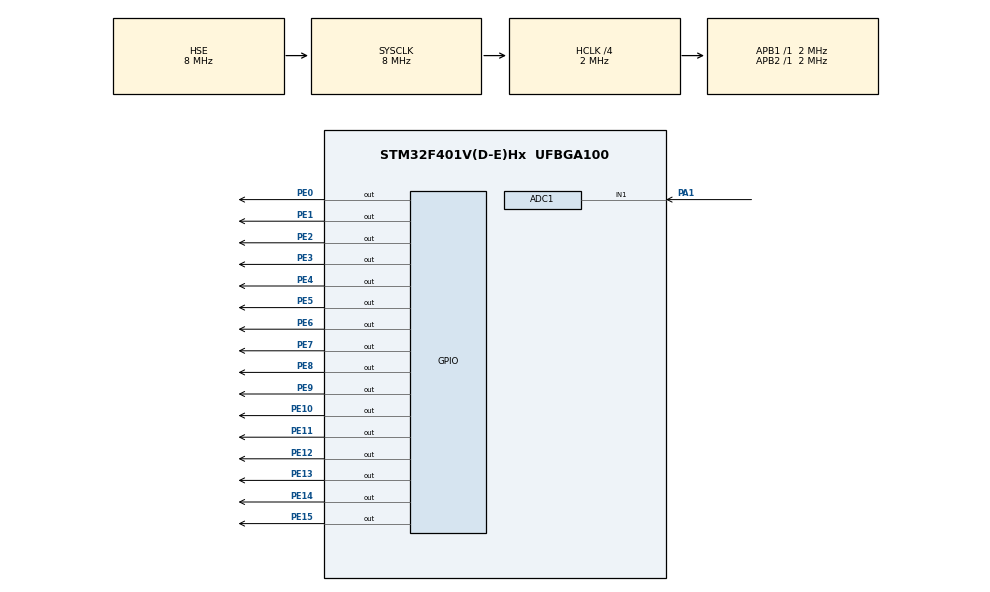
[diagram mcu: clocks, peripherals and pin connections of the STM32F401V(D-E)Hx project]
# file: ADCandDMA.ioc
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ADC1.Channel-1\#ChannelRegularConversion=ADC_CHANNEL_1
ADC1.ContinuousConvMode=ENABLE
ADC1.DMAContinuousRequests=DISABLE
ADC1.NbrOfConversion=1
ADC1.NbrOfConversionFlag=1
ADC1.Rank-1\#ChannelRegularConversion=1
ADC1.Resolution=ADC_RESOLUTION_10B
ADC1.SamplingTime-1\#ChannelRegularConversion=ADC_SAMPLETIME_84CYCLES
ADC1.ScanConvMode=DISABLE
ADC1.master=1
Mcu.Family=STM32F4
Mcu.Name=STM32F401V(D-E)Hx
Mcu.Package=UFBGA100
NVIC.ADC_IRQn=true\:0\:0\:false\:false\:true\:true\:true
NVIC.PriorityGroup=NVIC_PRIORITYGROUP_4
PA1.Signal=ADCx_IN1
PE0.GPIO_ModeDefaultOutputPP=GPIO_MODE_OUTPUT_PP
PE0.GPIO_PuPd=GPIO_NOPULL
PE0.GPIO_Speed=GPIO_SPEED_FREQ_HIGH
PE0.PinState=GPIO_PIN_RESET
PE0.Signal=GPIO_Output
PE1.GPIO_ModeDefaultOutputPP=GPIO_MODE_OUTPUT_PP
PE1.GPIO_PuPd=GPIO_NOPULL
PE1.GPIO_Speed=GPIO_SPEED_FREQ_HIGH
PE1.PinState=GPIO_PIN_RESET
PE1.Signal=GPIO_Output
PE10.GPIO_ModeDefaultOutputPP=GPIO_MODE_OUTPUT_PP
PE10.GPIO_PuPd=GPIO_NOPULL
PE10.GPIO_Speed=GPIO_SPEED_FREQ_HIGH
PE10.PinState=GPIO_PIN_RESET
PE10.Signal=GPIO_Output
PE11.GPIO_ModeDefaultOutputPP=GPIO_MODE_OUTPUT_PP
PE11.GPIO_PuPd=GPIO_NOPULL
PE11.GPIO_Speed=GPIO_SPEED_FREQ_HIGH
PE11.PinState=GPIO_PIN_RESET
PE11.Signal=GPIO_Output
PE12.GPIO_ModeDefaultOutputPP=GPIO_MODE_OUTPUT_PP
PE12.GPIO_PuPd=GPIO_NOPULL
PE12.GPIO_Speed=GPIO_SPEED_FREQ_HIGH
PE12.PinState=GPIO_PIN_RESET
PE12.Signal=GPIO_Output
PE13.GPIO_ModeDefaultOutputPP=GPIO_MODE_OUTPUT_PP
PE13.GPIO_PuPd=GPIO_NOPULL
PE13.GPIO_Speed=GPIO_SPEED_FREQ_HIGH
PE13.PinState=GPIO_PIN_RESET
PE13.Signal=GPIO_Output
PE14.GPIO_ModeDefaultOutputPP=GPIO_MODE_OUTPUT_PP
PE14.GPIO_PuPd=GPIO_NOPULL
PE14.GPIO_Speed=GPIO_SPEED_FREQ_HIGH
PE14.PinState=GPIO_PIN_RESET
PE14.Signal=GPIO_Output
PE15.Signal=GPIO_Output
PE2.GPIO_ModeDefaultOutputPP=GPIO_MODE_OUTPUT_PP
PE2.GPIO_PuPd=GPIO_NOPULL
PE2.GPIO_Speed=GPIO_SPEED_FREQ_HIGH
PE2.PinState=GPIO_PIN_RESET
PE2.Signal=GPIO_Output
PE3.GPIO_ModeDefaultOutputPP=GPIO_MODE_OUTPUT_PP
PE3.GPIO_PuPd=GPIO_NOPULL
PE3.GPIO_Speed=GPIO_SPEED_FREQ_HIGH
PE3.PinState=GPIO_PIN_RESET
PE3.Signal=GPIO_Output
PE4.GPIO_ModeDefaultOutputPP=GPIO_MODE_OUTPUT_PP
PE4.GPIO_PuPd=GPIO_NOPULL
PE4.GPIO_Speed=GPIO_SPEED_FREQ_HIGH
PE4.PinState=GPIO_PIN_RESET
PE4.Signal=GPIO_Output
PE5.GPIO_ModeDefaultOutputPP=GPIO_MODE_OUTPUT_PP
PE5.GPIO_PuPd=GPIO_NOPULL
PE5.GPIO_Speed=GPIO_SPEED_FREQ_HIGH
PE5.PinState=GPIO_PIN_RESET
PE5.Signal=GPIO_Output
PE6.GPIO_ModeDefaultOutputPP=GPIO_MODE_OUTPUT_PP
PE6.GPIO_PuPd=GPIO_NOPULL
PE6.GPIO_Speed=GPIO_SPEED_FREQ_HIGH
PE6.PinState=GPIO_PIN_RESET
PE6.Signal=GPIO_Output
PE7.GPIO_ModeDefaultOutputPP=GPIO_MODE_OUTPUT_PP
PE7.GPIO_PuPd=GPIO_NOPULL
PE7.GPIO_Speed=GPIO_SPEED_FREQ_HIGH
PE7.PinState=GPIO_PIN_RESET
PE7.Signal=GPIO_Output
PE8.GPIO_ModeDefaultOutputPP=GPIO_MODE_OUTPUT_PP
PE8.GPIO_PuPd=GPIO_NOPULL
PE8.GPIO_Speed=GPIO_SPEED_FREQ_HIGH
PE8.PinState=GPIO_PIN_RESET
PE8.Signal=GPIO_Output
PE9.GPIO_ModeDefaultOutputPP=GPIO_MODE_OUTPUT_PP
PE9.GPIO_PuPd=GPIO_NOPULL
PE9.GPIO_Speed=GPIO_SPEED_FREQ_HIGH
PE9.PinState=GPIO_PIN_RESET
PE9.Signal=GPIO_Output
PH0\ -\ OSC_IN.Mode=HSE-External-Oscillator
PH0\ -\ OSC_IN.Signal=RCC_OSC_IN
PH1\ -\ OSC_OUT.Mode=HSE-External-Oscillator
PH1\ -\ OSC_OUT.Signal=RCC_OSC_OUT
ProjectManager.HeapSize=0x200
ProjectManager.StackSize=0x400
ProjectManager.TargetToolchain=MDK-ARM V5.27
RCC.48MHZClocksFreq_Value=48000000
RCC.AHBCLKDivider=RCC_SYSCLK_DIV4
RCC.AHBFreq_Value=2000000
RCC.APB1Freq_Value=2000000
RCC.APB1TimFreq_Value=2000000
RCC.APB2Freq_Value=2000000
RCC.APB2TimFreq_Value=2000000
RCC.CortexFreq_Value=2000000
RCC.HCLKFreq_Value=2000000
RCC.HSE_VALUE=8000000
RCC.HSI_VALUE=16000000
RCC.LSE_VALUE=32768
RCC.PLLM=8
RCC.PLLSourceVirtual=RCC_PLLSOURCE_HSE
RCC.SYSCLKFreq_VALUE=8000000
RCC.SYSCLKSource=RCC_SYSCLKSOURCE_HSE
RCC.VCOOutputFreq_Value=192000000
SH.ADCx_IN1.0=ADC1_IN1,IN1
board=custom

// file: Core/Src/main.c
/* USER CODE BEGIN Header */
/**
  ******************************************************************************
  * @file           : main.c
  * @brief          : Main program body
  ******************************************************************************
  * @attention
  *
  * <h2><center>&copy; Copyright (c) 2022 STMicroelectronics.
  * All rights reserved.</center></h2>
  *
  * This software component is licensed by ST under BSD 3-Clause license,
  * the "License"; You may not use this file except in compliance with the
  * License. You may obtain a copy of the License at:
  *                        opensource.org/licenses/BSD-3-Clause
  *
  ******************************************************************************
  */
/* USER CODE END Header */
#include "main.h"

ADC_HandleTypeDef hadc1;

void SystemClock_Config(void);
static void MX_GPIO_Init(void);
static void MX_ADC1_Init(void);

int main(void)
{

  /* MCU Configuration--------------------------------------------------------*/

  /* Reset of all peripherals, Initializes the Flash interface and the Systick. */
  HAL_Init();

  /* Configure the system clock */
  SystemClock_Config();

  /* Initialize all configured peripherals */
  MX_GPIO_Init();
  MX_ADC1_Init();

  /* Infinite loop */
  /* USER CODE BEGIN WHILE */
	HAL_ADC_Start_IT(&hadc1);
	uint16_t adc_value;
  while (1)
  {
    /* USER CODE END WHILE */
		adc_value=HAL_ADC_GetValue(&hadc1);
		HAL_GPIO_WritePin(GPIOE,adc_value,GPIO_PIN_SET);
		HAL_GPIO_WritePin(GPIOE,~adc_value,GPIO_PIN_RESET);
  }
}

void SystemClock_Config(void)
{
  RCC_OscInitTypeDef RCC_OscInitStruct = {0};
  RCC_ClkInitTypeDef RCC_ClkInitStruct = {0};

  /** Configure the main internal regulator output voltage
  */
  __HAL_RCC_PWR_CLK_ENABLE();
  __HAL_PWR_VOLTAGESCALING_CONFIG(PWR_REGULATOR_VOLTAGE_SCALE2);
  /** Initializes the RCC Oscillators according to the specified parameters
  * in the RCC_OscInitTypeDef structure.
  */
  RCC_OscInitStruct.OscillatorType = RCC_OSCILLATORTYPE_HSE;
  RCC_OscInitStruct.HSEState = RCC_HSE_ON;
  RCC_OscInitStruct.PLL.PLLState = RCC_PLL_NONE;
  if (HAL_RCC_OscConfig(&RCC_OscInitStruct) != HAL_OK)
  {
    Error_Handler();
  }
  /** Initializes the CPU, AHB and APB buses clocks
  */
  RCC_ClkInitStruct.ClockType = RCC_CLOCKTYPE_HCLK|RCC_CLOCKTYPE_SYSCLK
                              |RCC_CLOCKTYPE_PCLK1|RCC_CLOCKTYPE_PCLK2;
  RCC_ClkInitStruct.SYSCLKSource = RCC_SYSCLKSOURCE_HSE;
  RCC_ClkInitStruct.AHBCLKDivider = RCC_SYSCLK_DIV4;
  RCC_ClkInitStruct.APB1CLKDivider = RCC_HCLK_DIV1;
  RCC_ClkInitStruct.APB2CLKDivider = RCC_HCLK_DIV1;

  if (HAL_RCC_ClockConfig(&RCC_ClkInitStruct, FLASH_LATENCY_0) != HAL_OK)
  {
    Error_Handler();
  }
}

static void MX_ADC1_Init(void)
{

  ADC_ChannelConfTypeDef sConfig = {0};

  /** Configure the global features of the ADC (Clock, Resolution, Data Alignment and number of conversion)
  */
  hadc1.Instance = ADC1;
  hadc1.Init.ClockPrescaler = ADC_CLOCK_SYNC_PCLK_DIV2;
  hadc1.Init.Resolution = ADC_RESOLUTION_10B;
  hadc1.Init.ScanConvMode = DISABLE;
  hadc1.Init.ContinuousConvMode = ENABLE;
  hadc1.Init.DiscontinuousConvMode = DISABLE;
  hadc1.Init.ExternalTrigConvEdge = ADC_EXTERNALTRIGCONVEDGE_NONE;
  hadc1.Init.ExternalTrigConv = ADC_SOFTWARE_START;
  hadc1.Init.DataAlign = ADC_DATAALIGN_RIGHT;
  hadc1.Init.NbrOfConversion = 1;
  hadc1.Init.DMAContinuousRequests = DISABLE;
  hadc1.Init.EOCSelection = ADC_EOC_SINGLE_CONV;
  if (HAL_ADC_Init(&hadc1) != HAL_OK)
  {
    Error_Handler();
  }
  /** Configure for the selected ADC regular channel its corresponding rank in the sequencer and its sample time.
  */
  sConfig.Channel = ADC_CHANNEL_1;
  sConfig.Rank = 1;
  sConfig.SamplingTime = ADC_SAMPLETIME_84CYCLES;
  if (HAL_ADC_ConfigChannel(&hadc1, &sConfig) != HAL_OK)
  {
    Error_Handler();
  }

}

static void MX_GPIO_Init(void)
{
  GPIO_InitTypeDef GPIO_InitStruct = {0};

  /* GPIO Ports Clock Enable */
  __HAL_RCC_GPIOE_CLK_ENABLE();
  __HAL_RCC_GPIOH_CLK_ENABLE();
  __HAL_RCC_GPIOA_CLK_ENABLE();

  /*Configure GPIO pin Output Level */
  HAL_GPIO_WritePin(GPIOE, GPIO_PIN_3|GPIO_PIN_1|GPIO_PIN_4|GPIO_PIN_2
                          |GPIO_PIN_5|GPIO_PIN_0|GPIO_PIN_6|GPIO_PIN_8
                          |GPIO_PIN_10|GPIO_PIN_12|GPIO_PIN_7|GPIO_PIN_9
                          |GPIO_PIN_11|GPIO_PIN_13|GPIO_PIN_14|GPIO_PIN_15, GPIO_PIN_RESET);

  /*Configure GPIO pins : PE3 PE1 PE4 PE2
                           PE5 PE0 PE6 PE8
                           PE10 PE12 PE7 PE9
                           PE11 PE13 PE14 */
  GPIO_InitStruct.Pin = GPIO_PIN_3|GPIO_PIN_1|GPIO_PIN_4|GPIO_PIN_2
                          |GPIO_PIN_5|GPIO_PIN_0|GPIO_PIN_6|GPIO_PIN_8
                          |GPIO_PIN_10|GPIO_PIN_12|GPIO_PIN_7|GPIO_PIN_9
                          |GPIO_PIN_11|GPIO_PIN_13|GPIO_PIN_14;
  GPIO_InitStruct.Mode = GPIO_MODE_OUTPUT_PP;
  GPIO_InitStruct.Pull = GPIO_NOPULL;
  GPIO_InitStruct.Speed = GPIO_SPEED_FREQ_HIGH;
  HAL_GPIO_Init(GPIOE, &GPIO_InitStruct);

  /*Configure GPIO pin : PE15 */
  GPIO_InitStruct.Pin = GPIO_PIN_15;
  GPIO_InitStruct.Mode = GPIO_MODE_OUTPUT_PP;
  GPIO_InitStruct.Pull = GPIO_NOPULL;
  GPIO_InitStruct.Speed = GPIO_SPEED_FREQ_LOW;
  HAL_GPIO_Init(GPIOE, &GPIO_InitStruct);

}

void Error_Handler(void)
{
  __disable_irq();
  while (1)
  {
  }
}

/************************ (C) COPYRIGHT STMicroelectronics *****END OF FILE****/
